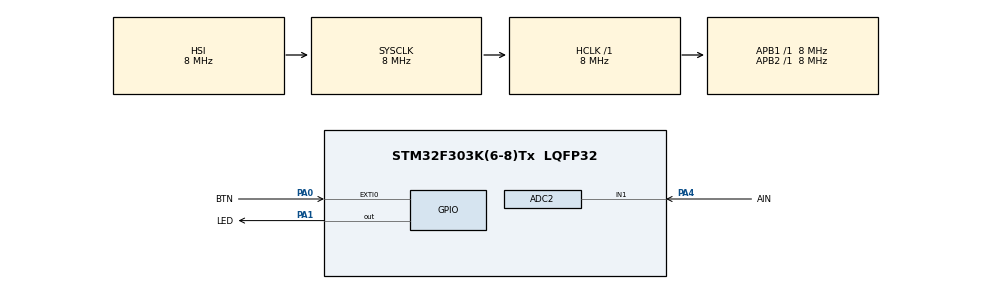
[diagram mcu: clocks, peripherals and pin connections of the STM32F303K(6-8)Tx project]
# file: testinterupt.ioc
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ADC2.Channel-0\#ChannelRegularConversion=ADC_CHANNEL_1
ADC2.ContinuousConvMode=ENABLE
ADC2.DMAContinuousRequests=ENABLE
ADC2.NbrOfConversionFlag=1
ADC2.Offset-0\#ChannelRegularConversion=0
ADC2.OffsetNumber-0\#ChannelRegularConversion=ADC_OFFSET_NONE
ADC2.Rank-0\#ChannelRegularConversion=1
ADC2.SamplingTime-0\#ChannelRegularConversion=ADC_SAMPLETIME_1CYCLE_5
ADC2.SamplingTimeOPAMP-0\#ChannelRegularConversion=ADC_SAMPLETIME_7CYCLES_5
ADC2.SubFamily=STM32F303x8
Dma.ADC2.0.Direction=DMA_PERIPH_TO_MEMORY
Dma.ADC2.0.Instance=DMA1_Channel2
Dma.ADC2.0.MemDataAlignment=DMA_MDATAALIGN_HALFWORD
Dma.ADC2.0.MemInc=DMA_MINC_ENABLE
Dma.ADC2.0.Mode=DMA_CIRCULAR
Dma.ADC2.0.PeriphDataAlignment=DMA_PDATAALIGN_HALFWORD
Dma.ADC2.0.PeriphInc=DMA_PINC_DISABLE
Dma.ADC2.0.Priority=DMA_PRIORITY_LOW
Dma.Request0=ADC2
Mcu.Family=STM32F3
Mcu.Name=STM32F303K(6-8)Tx
Mcu.Package=LQFP32
NVIC.DMA1_Channel2_IRQn=true\:0\:0\:false\:false\:true\:false\:true\:true
NVIC.EXTI0_IRQn=true\:0\:0\:false\:false\:true\:true\:true\:true
NVIC.PriorityGroup=NVIC_PRIORITYGROUP_4
NVIC.TIM7_DAC2_IRQn=true\:0\:0\:false\:false\:true\:true\:true\:true
PA0.GPIO_Label=BTN
PA0.GPIO_PuPd=GPIO_PULLUP
PA0.Signal=GPXTI0
PA1.GPIO_Label=LED
PA1.Signal=GPIO_Output
PA4.GPIO_Label=AIN
PA4.Signal=SharedAnalog_PA4
ProjectManager.HeapSize=0x200
ProjectManager.StackSize=0x400
ProjectManager.TargetToolchain=STM32CubeIDE
RCC.AHBFreq_Value=8000000
RCC.APB1Freq_Value=8000000
RCC.APB2Freq_Value=8000000
RCC.CortexFreq_Value=8000000
RCC.HSE_VALUE=8000000
RCC.HSI_VALUE=8000000
RCC.PLLMUL=RCC_PLL_MUL4
RCC.SYSCLKFreq_VALUE=8000000
SH.SharedAnalog_PA4.0=GPIO_Analog
SH.SharedAnalog_PA4.1=ADC2_IN1,IN1-Single-Ended
TIM7.Period=1000
TIM7.Prescaler=799
VP_TIM7_VS_ClockSourceINT.Mode=Enable_Timer
board=custom

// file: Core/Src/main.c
/* USER CODE BEGIN Header */
/**
  ******************************************************************************
  * @file           : main.c
  * @brief          : Main program body
  ******************************************************************************
  * @attention
  *
  * Copyright (c) 2024 STMicroelectronics.
  * All rights reserved.
  *
  * This software is licensed under terms that can be found in the LICENSE file
  * in the root directory of this software component.
  * If no LICENSE file comes with this software, it is provided AS-IS.
  *
  ******************************************************************************
  */
/* USER CODE END Header */
#include "main.h"

ADC_HandleTypeDef hadc2;
DMA_HandleTypeDef hdma_adc2;

TIM_HandleTypeDef htim7;

/* USER CODE BEGIN PV */
unsigned int ledState = 0;
unsigned int ticks = 0;
uint32_t value_adc;
/* USER CODE END PV */

void SystemClock_Config(void);
static void MX_GPIO_Init(void);
static void MX_DMA_Init(void);
static void MX_TIM7_Init(void);
static void MX_ADC2_Init(void);

int main(void)
{

  /* MCU Configuration--------------------------------------------------------*/

  /* Reset of all peripherals, Initializes the Flash interface and the Systick. */
  HAL_Init();

  /* Configure the system clock */
  SystemClock_Config();

  /* Initialize all configured peripherals */
  MX_GPIO_Init();
  MX_DMA_Init();
  MX_TIM7_Init();
  MX_ADC2_Init();
  /* USER CODE BEGIN 2 */
  HAL_ADCEx_Calibration_Start(&hadc2, ADC_SINGLE_ENDED);
  HAL_ADC_Start_DMA(&hadc2,(uint32_t*)&value_adc,1);
  // This copies the value from the ADC directly into memory
  /* USER CODE END 2 */

  /* Infinite loop */
  while (1)
  {

  }
}

void SystemClock_Config(void)
{
  RCC_OscInitTypeDef RCC_OscInitStruct = {0};
  RCC_ClkInitTypeDef RCC_ClkInitStruct = {0};
  RCC_PeriphCLKInitTypeDef PeriphClkInit = {0};

  /** Initializes the RCC Oscillators according to the specified parameters
  * in the RCC_OscInitTypeDef structure.
  */
  RCC_OscInitStruct.OscillatorType = RCC_OSCILLATORTYPE_HSI;
  RCC_OscInitStruct.HSIState = RCC_HSI_ON;
  RCC_OscInitStruct.HSICalibrationValue = RCC_HSICALIBRATION_DEFAULT;
  RCC_OscInitStruct.PLL.PLLState = RCC_PLL_ON;
  RCC_OscInitStruct.PLL.PLLSource = RCC_PLLSOURCE_HSI;
  RCC_OscInitStruct.PLL.PLLMUL = RCC_PLL_MUL4;
  if (HAL_RCC_OscConfig(&RCC_OscInitStruct) != HAL_OK)
  {
    Error_Handler();
  }

  /** Initializes the CPU, AHB and APB buses clocks
  */
  RCC_ClkInitStruct.ClockType = RCC_CLOCKTYPE_HCLK|RCC_CLOCKTYPE_SYSCLK
                              |RCC_CLOCKTYPE_PCLK1|RCC_CLOCKTYPE_PCLK2;
  RCC_ClkInitStruct.SYSCLKSource = RCC_SYSCLKSOURCE_HSI;
  RCC_ClkInitStruct.AHBCLKDivider = RCC_SYSCLK_DIV1;
  RCC_ClkInitStruct.APB1CLKDivider = RCC_HCLK_DIV1;
  RCC_ClkInitStruct.APB2CLKDivider = RCC_HCLK_DIV1;

  if (HAL_RCC_ClockConfig(&RCC_ClkInitStruct, FLASH_LATENCY_0) != HAL_OK)
  {
    Error_Handler();
  }
  PeriphClkInit.PeriphClockSelection = RCC_PERIPHCLK_ADC12;
  PeriphClkInit.Adc12ClockSelection = RCC_ADC12PLLCLK_DIV1;
  if (HAL_RCCEx_PeriphCLKConfig(&PeriphClkInit) != HAL_OK)
  {
    Error_Handler();
  }
}

static void MX_ADC2_Init(void)
{

  ADC_ChannelConfTypeDef sConfig = {0};

  /** Common config
  */
  hadc2.Instance = ADC2;
  hadc2.Init.ClockPrescaler = ADC_CLOCK_ASYNC_DIV1;
  hadc2.Init.Resolution = ADC_RESOLUTION_12B;
  hadc2.Init.ScanConvMode = ADC_SCAN_DISABLE;
  hadc2.Init.ContinuousConvMode = ENABLE;
  hadc2.Init.DiscontinuousConvMode = DISABLE;
  hadc2.Init.ExternalTrigConvEdge = ADC_EXTERNALTRIGCONVEDGE_NONE;
  hadc2.Init.ExternalTrigConv = ADC_SOFTWARE_START;
  hadc2.Init.DataAlign = ADC_DATAALIGN_RIGHT;
  hadc2.Init.NbrOfConversion = 1;
  hadc2.Init.DMAContinuousRequests = ENABLE;
  hadc2.Init.EOCSelection = ADC_EOC_SINGLE_CONV;
  hadc2.Init.LowPowerAutoWait = DISABLE;
  hadc2.Init.Overrun = ADC_OVR_DATA_OVERWRITTEN;
  if (HAL_ADC_Init(&hadc2) != HAL_OK)
  {
    Error_Handler();
  }

  /** Configure Regular Channel
  */
  sConfig.Channel = ADC_CHANNEL_1;
  sConfig.Rank = ADC_REGULAR_RANK_1;
  sConfig.SingleDiff = ADC_SINGLE_ENDED;
  sConfig.SamplingTime = ADC_SAMPLETIME_1CYCLE_5;
  sConfig.OffsetNumber = ADC_OFFSET_NONE;
  sConfig.Offset = 0;
  if (HAL_ADC_ConfigChannel(&hadc2, &sConfig) != HAL_OK)
  {
    Error_Handler();
  }

}

static void MX_TIM7_Init(void)
{

  TIM_MasterConfigTypeDef sMasterConfig = {0};

  htim7.Instance = TIM7;
  htim7.Init.Prescaler = 799;
  htim7.Init.CounterMode = TIM_COUNTERMODE_UP;
  htim7.Init.Period = 1000;
  htim7.Init.AutoReloadPreload = TIM_AUTORELOAD_PRELOAD_DISABLE;
  if (HAL_TIM_Base_Init(&htim7) != HAL_OK)
  {
    Error_Handler();
  }
  sMasterConfig.MasterOutputTrigger = TIM_TRGO_RESET;
  sMasterConfig.MasterSlaveMode = TIM_MASTERSLAVEMODE_DISABLE;
  if (HAL_TIMEx_MasterConfigSynchronization(&htim7, &sMasterConfig) != HAL_OK)
  {
    Error_Handler();
  }

}

static void MX_DMA_Init(void)
{

  /* DMA controller clock enable */
  __HAL_RCC_DMA1_CLK_ENABLE();

  /* DMA interrupt init */
  /* DMA1_Channel2_IRQn interrupt configuration */
  HAL_NVIC_SetPriority(DMA1_Channel2_IRQn, 0, 0);
  HAL_NVIC_EnableIRQ(DMA1_Channel2_IRQn);

}

static void MX_GPIO_Init(void)
{
  GPIO_InitTypeDef GPIO_InitStruct = {0};

  /* GPIO Ports Clock Enable */
  __HAL_RCC_GPIOA_CLK_ENABLE();

  /*Configure GPIO pin Output Level */
  HAL_GPIO_WritePin(LED_GPIO_Port, LED_Pin, GPIO_PIN_RESET);

  /*Configure GPIO pin : BTN_Pin */
  GPIO_InitStruct.Pin = BTN_Pin;
  GPIO_InitStruct.Mode = GPIO_MODE_IT_RISING;
  GPIO_InitStruct.Pull = GPIO_PULLUP;
  HAL_GPIO_Init(BTN_GPIO_Port, &GPIO_InitStruct);

  /*Configure GPIO pin : LED_Pin */
  GPIO_InitStruct.Pin = LED_Pin;
  GPIO_InitStruct.Mode = GPIO_MODE_OUTPUT_PP;
  GPIO_InitStruct.Pull = GPIO_NOPULL;
  GPIO_InitStruct.Speed = GPIO_SPEED_FREQ_LOW;
  HAL_GPIO_Init(LED_GPIO_Port, &GPIO_InitStruct);

  /* EXTI interrupt init*/
  HAL_NVIC_SetPriority(EXTI0_IRQn, 0, 0);
  HAL_NVIC_EnableIRQ(EXTI0_IRQn);

}

/* USER CODE BEGIN 4 */
void ledStateChange() {
	ledState ^= 1;
}

void eachTick() {
	ticks++;
	if (ledState) {
    if (ticks % 10 == 0) {
    //if (ticks % (value_adc / 205) == 0) {
      HAL_GPIO_TogglePin(LED_GPIO_Port, LED_Pin);
    }
  } else {
    HAL_GPIO_WritePin(LED_GPIO_Port, LED_Pin, GPIO_PIN_RESET);
  }
}

/* USER CODE END 4 */

void Error_Handler(void)
{
  __disable_irq();
  while (1)
  {
  }
}
